# M440 register map
File version: 0.1
Registers are 32-bit, read-write, reset 0x0 unless marked. A register's access mark holds for its fields unless they carry their own. Offsets are from the block's base; [hi:lo] are bit positions; {n}, {i} and the like mark numbered series.

## EPHC_MIR — Enhannced Two Aspect Pulse Input Counter (Enhannced 2-Phase Pulse Input Timer) (EPHC) for PSC
Base 0x40075000
0x1C ADAT reset 0x7FFF — EPHC 16-bit Counter Read Register
  [15:0] DAT
0x28 BUC ro — EPHC 24-bit Counter Read Register
  [23:0] T24UCR
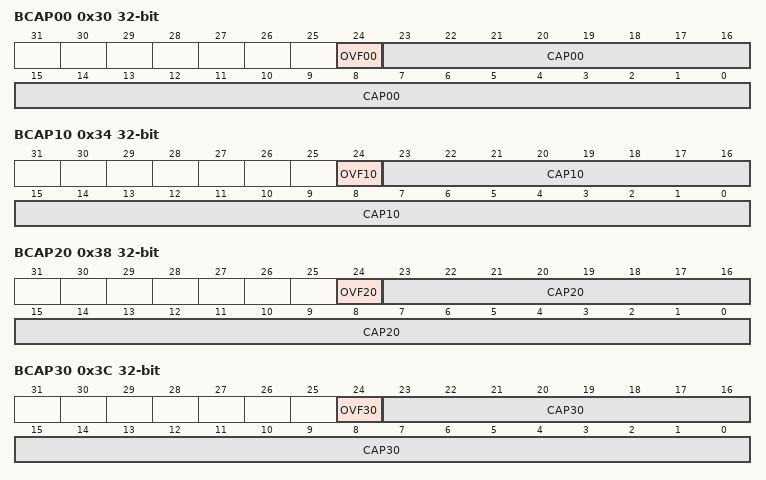
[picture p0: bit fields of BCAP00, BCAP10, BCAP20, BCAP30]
0x30 BCAP00 ro — EPHC Capture 00 Register
  [24] OVF00, [23:0] CAP00
0x34 BCAP10 ro — EPHC Capture 10 Register
  [24] OVF10, [23:0] CAP10
0x38 BCAP20 ro — EPHC Capture 20 Register
  [24] OVF20, [23:0] CAP20
0x3C BCAP30 ro — EPHC Capture 30 Register
  [24] OVF30, [23:0] CAP30
{0x40+4i} B{i}DAT ro (i=0..3) — EPHC Cycle {i} Register
  [23:0] B{i}DAT
0x50 BCDAT ro — EPHC Cycle Common Register
  [23:0] BCDAT
{0x60+4i} B{i}PDT ro (i=0..3) — EPHC Phase DifferEPHCe {i} Register
  [23:0] B{i}PDT

## ESIO0 — Enhannced Serial I_O (ESIO)
Base 0x4406A000
Same registers: ESIO1 0x4406B000, ESIO2 0x4406C000
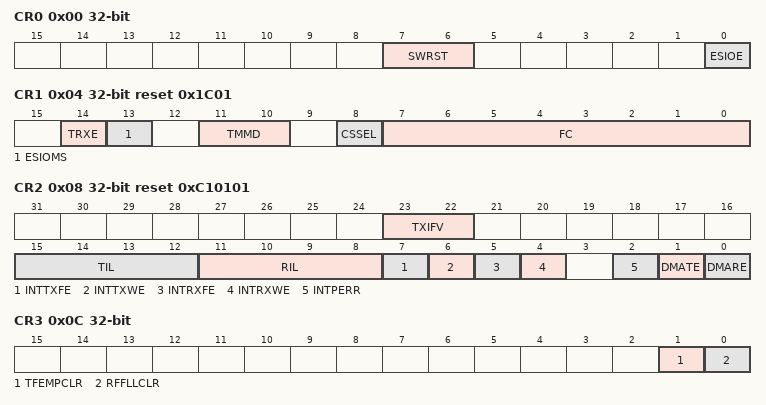
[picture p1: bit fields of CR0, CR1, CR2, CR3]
0x00 CR0 — ESIO Control Register 0
  [7:6] SWRST wo, [0] ESIOE
0x04 CR1 reset 0x1C01 — ESIO Control Register 1
  [14] TRXE, [13] ESIOMS, [11:10] TMMD, [8] CSSEL, [7:0] FC
0x08 CR2 reset 0xC10101 — ESIO Control Register 2
  [23:22] TXIFV, [15:12] TIL, [11:8] RIL, [7] INTTXFE, [6] INTTXWE, [5] INTRXFE, [4] INTRXWE, [2] INTPERR, [1] DMATE, [0] DMARE
0x0C CR3 — ESIO Control Register 3
  [1] TFEMPCLR wo, [0] RFFLLCLR wo
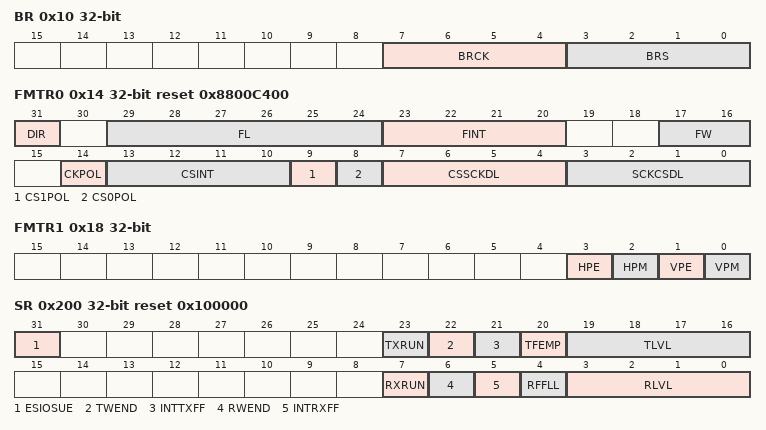
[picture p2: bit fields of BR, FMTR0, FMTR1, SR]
0x10 BR — ESIO Baud Rate Generator Control Register
  [7:4] BRCK, [3:0] BRS
0x14 FMTR0 reset 0x8800C400 — ESIO Format Control Register 0
  [31] DIR, [29:24] FL, [23:20] FINT, [17:16] FW, [14] CKPOL, [13:10] CSINT, [9] CS1POL, [8] CS0POL, [7:4] CSSCKDL, [3:0] SCKCSDL
0x18 FMTR1 — ESIO Format Control Register 1
  [3] HPE, [2] HPM, [1] VPE, [0] VPM
0x100 DR — ESIO Data Register
  [30:0] ESIODR
0x200 SR reset 0x100000 — ESIO Status Register
  [31] ESIOSUE ro, [23] TXRUN ro, [22] TWEND, [21] INTTXFF, [20] TFEMP ro, [19:16] TLVL ro, [7] RXRUN ro, [6] RWEND, [5] INTRXFF, [4] RFFLL ro, [3:0] RLVL ro
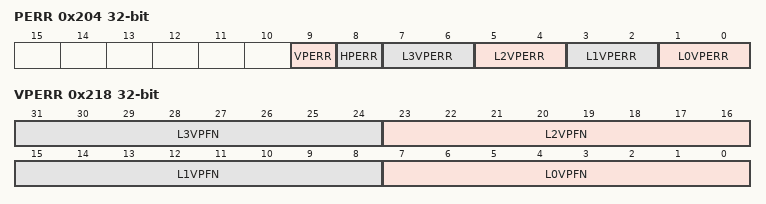
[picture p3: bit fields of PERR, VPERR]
0x204 PERR — ESIO Parity Error Flag Register
  [9] VPERR, [8] HPERR, [2n+1:2n] L{n}VPERR (n=0..3)
{0x208+4i} HPERR{i} (i=0..3) — ESIO Horizontal Parity Error Register {i}
  [30:0] L{i}HP
0x218 VPERR — ESIO Vertical Parity Error Frame Number Register
  [8n+7:8n] L{n}VPFN (n=0..3)

## PA — Port A
Base 0x400C0000
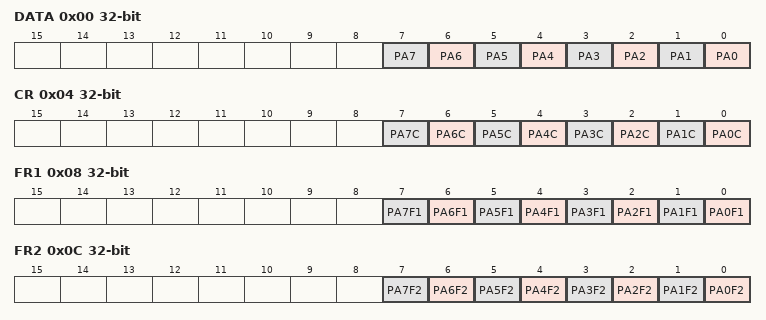
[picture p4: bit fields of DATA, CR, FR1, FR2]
0x00 DATA — Port A Data Register
  [n] PA{n} (n=0..7)
0x04 CR — Port A Output Control Register
  [n] PA{n}C (n=0..7)
0x08 FR1 — Port A Function Register 1
  [n] PA{n}F1 (n=0..7)
0x0C FR2 — Port A Function Register 2
  [n] PA{n}F2 (n=0..7)
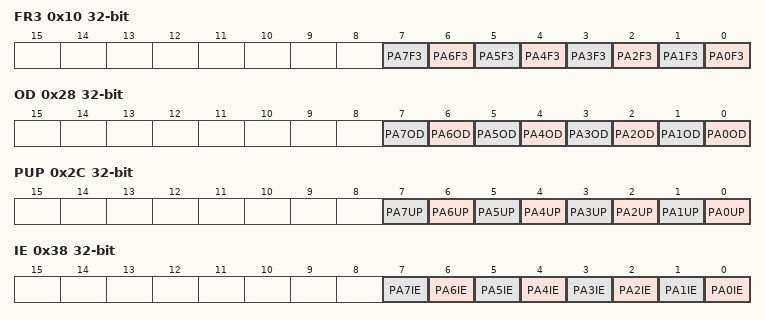
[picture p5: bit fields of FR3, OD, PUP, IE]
0x10 FR3 — Port A Function Register 2
  [n] PA{n}F3 (n=0..7)
0x28 OD — Port A Open Drain Control Register
  [n] PA{n}OD (n=0..7)
0x2C PUP — Port A Pull-up Control Register
  [n] PA{n}UP (n=0..7)
0x38 IE — Port A Input Control Register
  [n] PA{n}IE (n=0..7)

## PB — Port B
Base 0x400C0100
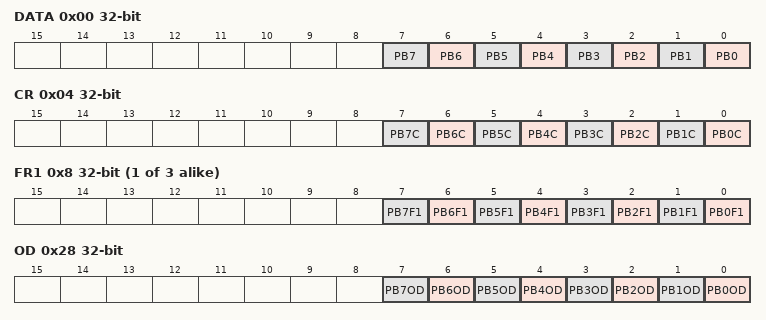
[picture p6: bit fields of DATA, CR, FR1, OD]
0x00 DATA — Port B Data Register
  [n] PB{n} (n=0..7)
0x04 CR — Port B Output Control Register
  [n] PB{n}C (n=0..7)
{0x4+4i} FR{i} (i=1..3) — Port B Function Register {i}
  [n] PB{n}F{i} (n=0..7)
0x28 OD — Port B Open Drain Control Register
  [n] PB{n}OD (n=0..7)
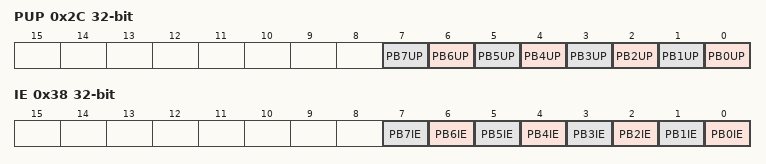
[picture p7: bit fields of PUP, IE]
0x2C PUP — Port B Pull-up Control Register
  [n] PB{n}UP (n=0..7)
0x38 IE — Port B Input Control Register
  [n] PB{n}IE (n=0..7)

## PC — Port C
Base 0x400C0200
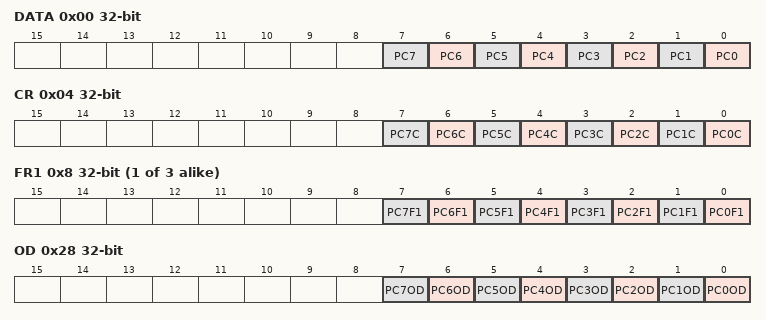
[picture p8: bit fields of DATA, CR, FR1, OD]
0x00 DATA — Port C Data Register
  [n] PC{n} (n=0..7)
0x04 CR — Port C Output Control Register
  [n] PC{n}C (n=0..7)
{0x4+4i} FR{i} (i=1..3) — Port C Function Register {i}
  [n] PC{n}F{i} (n=0..7)
0x28 OD — Port C Open Drain Control Register
  [n] PC{n}OD (n=0..7)
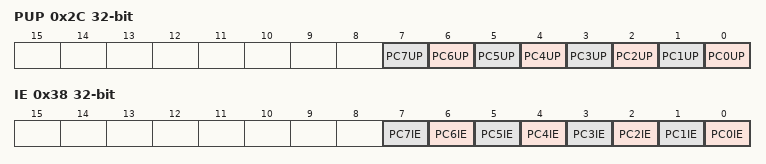
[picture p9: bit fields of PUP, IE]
0x2C PUP — Port C Pull-up Control Register
  [n] PC{n}UP (n=0..7)
0x38 IE — Port C Input Control Register
  [n] PC{n}IE (n=0..7)

## PD — Port D
Base 0x400C0300
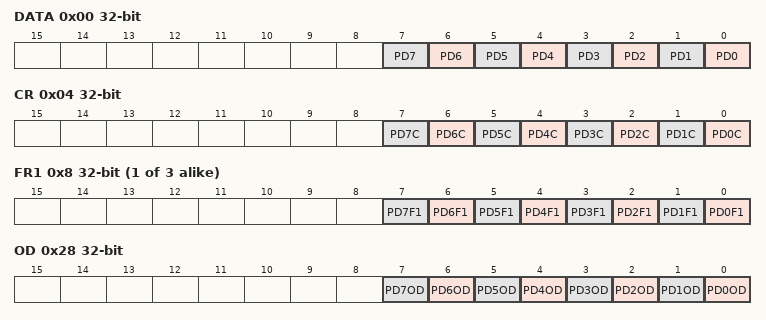
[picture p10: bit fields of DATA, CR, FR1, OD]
0x00 DATA — Port D Data Register
  [n] PD{n} (n=0..7)
0x04 CR — Port D Output Control Register
  [n] PD{n}C (n=0..7)
{0x4+4i} FR{i} (i=1..3) — Port D Function Register {i}
  [n] PD{n}F{i} (n=0..7)
0x28 OD — Port D Open Drain Control Register
  [n] PD{n}OD (n=0..7)
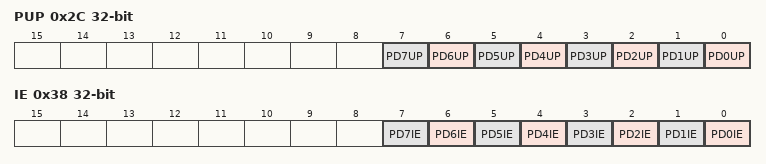
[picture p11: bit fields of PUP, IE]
0x2C PUP — Port D Pull-up Control Register
  [n] PD{n}UP (n=0..7)
0x38 IE — Port D Input Control Register
  [n] PD{n}IE (n=0..7)
